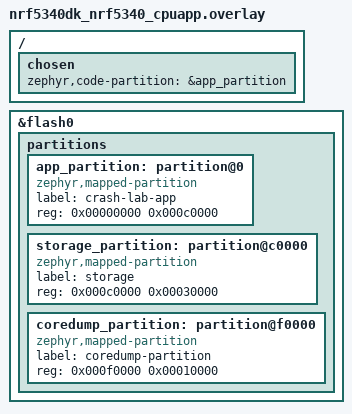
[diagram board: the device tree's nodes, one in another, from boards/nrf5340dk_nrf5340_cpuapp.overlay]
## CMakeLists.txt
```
cmake_minimum_required(VERSION 3.20.0)

list(APPEND ZEPHYR_EXTRA_MODULES "${CMAKE_CURRENT_SOURCE_DIR}")
find_package(Zephyr REQUIRED HINTS $ENV{ZEPHYR_BASE})
project(nrf5340_crash_ble_lab)

execute_process(
  COMMAND git rev-parse --short=12 HEAD
  WORKING_DIRECTORY ${CMAKE_CURRENT_SOURCE_DIR}
  OUTPUT_VARIABLE CRASH_LAB_GIT_SHA
  OUTPUT_STRIP_TRAILING_WHITESPACE
  ERROR_QUIET
)
if(NOT CRASH_LAB_GIT_SHA)
  set(CRASH_LAB_GIT_SHA "uncommitted")
endif()

# A commit without an intervening source edit must also refresh the ID on
# incremental builds (including repositories whose .git is a worktree file).
execute_process(COMMAND git symbolic-ref -q HEAD
  WORKING_DIRECTORY ${CMAKE_CURRENT_SOURCE_DIR}
  OUTPUT_VARIABLE CRASH_LAB_GIT_REF OUTPUT_STRIP_TRAILING_WHITESPACE ERROR_QUIET)
foreach(git_path IN ITEMS HEAD "${CRASH_LAB_GIT_REF}")
  if(git_path)
    execute_process(COMMAND git rev-parse --git-path "${git_path}"
      WORKING_DIRECTORY ${CMAKE_CURRENT_SOURCE_DIR}
      OUTPUT_VARIABLE ref_path OUTPUT_STRIP_TRAILING_WHITESPACE ERROR_QUIET)
    if(ref_path)
      get_filename_component(ref_path "${ref_path}" ABSOLUTE
        BASE_DIR "${CMAKE_CURRENT_SOURCE_DIR}")
      if(EXISTS "${ref_path}")
        set_property(DIRECTORY APPEND PROPERTY CMAKE_CONFIGURE_DEPENDS "${ref_path}")
      endif()
    endif()
  endif()
endforeach()

# A source/config fingerprint travels in BLE status and metadata. Keep the
# unstripped ELF from this build: matching the fingerprint is necessary but
# not a substitute for archiving the precise ELF used to flash the target.
set(CRASH_LAB_INPUTS CMakeLists.txt Kconfig prj.conf sysbuild.conf
  boards/nrf5340dk_nrf5340_cpuapp.overlay
  src/main.c src/crashes.c src/dummy_ble.c src/dump_store.c src/flash_coredump.c
  src/crashes.h src/dummy_ble.h src/dump_store.h src/diagnostics.h src/flash_coredump.h
  sdk/zephyr/src/diag_sdk.c sdk/zephyr/include/diag_sdk/diag_sdk.h
  sdk/zephyr/Kconfig sdk/zephyr/CMakeLists.txt sdk/zephyr/zephyr/module.yml
  zephyr/module.yml)
set(CRASH_LAB_FINGERPRINT "git:${CRASH_LAB_GIT_SHA}\n")
foreach(input IN LISTS CRASH_LAB_INPUTS)
  # A source edit must reconfigure, not just recompile: otherwise a different
  # ELF could advertise an old fingerprint and mis-symbolicate saved events.
  set_property(DIRECTORY APPEND PROPERTY CMAKE_CONFIGURE_DEPENDS
    "${CMAKE_CURRENT_SOURCE_DIR}/${input}")
  file(SHA256 "${CMAKE_CURRENT_SOURCE_DIR}/${input}" digest)
  string(APPEND CRASH_LAB_FINGERPRINT "${input}:${digest}\n")
endforeach()
if(EXISTS "${CMAKE_CURRENT_BINARY_DIR}/zephyr/.config")
  file(SHA256 "${CMAKE_CURRENT_BINARY_DIR}/zephyr/.config" config_digest)
  string(APPEND CRASH_LAB_FINGERPRINT "config:${config_digest}\n")
endif()
string(SHA256 CRASH_LAB_BUILD_FINGERPRINT "${CRASH_LAB_FINGERPRINT}")
string(SUBSTRING "${CRASH_LAB_BUILD_FINGERPRINT}" 0 20 CRASH_LAB_BUILD_FINGERPRINT)

configure_file(src/build_id.h.in ${CMAKE_CURRENT_BINARY_DIR}/generated/build_id.h @ONLY)
target_include_directories(app PRIVATE src ${CMAKE_CURRENT_BINARY_DIR}/generated)

target_sources(app PRIVATE
  src/main.c
  src/crashes.c
  src/dummy_ble.c
  src/dump_store.c
  src/flash_coredump.c
)

# Preserve usable Cortex-M call frames in the unstripped ELF.
target_compile_options(app PRIVATE -fno-omit-frame-pointer -fno-optimize-sibling-calls)
```

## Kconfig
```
mainmenu "nRF5340 crash-over-BLE lab"

source "Kconfig.zephyr"

menu "Crash lab"

config CRASH_LAB_VERSION
	string "Build identifier"
	default "lab-1"
	help
	  Human-readable identifier embedded in firmware and dump metadata.

config CRASH_LAB_AUTO_CRASH
	bool "Enable periodic random crashes"
	default n
	help
	  Keep disabled for first bring-up so BLE remains reachable.

config CRASH_LAB_AUTO_CRASH_SECONDS
	int "Seconds between automatic crashes"
	default 60
	range 10 3600
	depends on CRASH_LAB_AUTO_CRASH

config CRASH_LAB_STACK_SMASH
	bool "Enable optional stack-smash crash type"
	default n
	help
	  Adds crash type 4. Types 0..3 are always available.

config CRASH_LAB_UNSAFE_BLE_COMMANDS
	bool "Allow unauthenticated destructive BLE lab commands"
	default n
	help
	  Exposes intentional crash, reboot, evidence-clear, and synthetic event
	  commands through the custom GATT characteristic. This is only appropriate
	  for an isolated development bench. Leave disabled in derived firmware.

endmenu
```

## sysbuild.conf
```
# The application core uses the network core as the BLE HCI controller.
SB_CONFIG_NETCORE_HCI_IPC=y

# No MCUboot and no OTA slots: this is a wired-flash-only lab image.
SB_CONFIG_BOOTLOADER_MCUBOOT=n
SB_CONFIG_PARTITION_MANAGER=n
```

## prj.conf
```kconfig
# Core runtime
CONFIG_MAIN_STACK_SIZE=4096
CONFIG_SYSTEM_WORKQUEUE_STACK_SIZE=4096
CONFIG_HEAP_MEM_POOL_SIZE=8192
CONFIG_REBOOT=y
CONFIG_HWINFO=y
CONFIG_GPIO=y
CONFIG_ASSERT=y
CONFIG_ASSERT_VERBOSE=y
CONFIG_THREAD_NAME=y
CONFIG_EXTRA_EXCEPTION_INFO=y
CONFIG_DEBUG_OPTIMIZATIONS=y
CONFIG_NO_OPTIMIZATIONS=n
CONFIG_INIT_STACKS=y
CONFIG_STACK_SENTINEL=y
CONFIG_HW_STACK_PROTECTION=y
CONFIG_NULL_POINTER_EXCEPTION_DETECTION_DWT=y

# UART debug stream
CONFIG_SERIAL=y
CONFIG_CONSOLE=y
CONFIG_UART_CONSOLE=y
CONFIG_LOG=y
CONFIG_LOG_MODE_DEFERRED=y
CONFIG_LOG_PROCESS_THREAD_STACK_SIZE=2048
CONFIG_LOG_DEFAULT_LEVEL=3
CONFIG_LOG_MAX_LEVEL=3
CONFIG_LOG_BACKEND_UART=y
CONFIG_LOG_BACKEND_FS=y
CONFIG_LOG_BACKEND_FS_AUTOSTART=n
CONFIG_LOG_BACKEND_FS_DIR="/lfs"
CONFIG_LOG_BACKEND_FS_FILE_PREFIX="zephyr."
CONFIG_LOG_BACKEND_FS_FILE_SIZE=8192
CONFIG_LOG_BACKEND_FS_FILES_LIMIT=4
CONFIG_PRINTK=y
CONFIG_LOG_PRINTK=n

# BLE peripheral on app core; HCI controller comes from hci_ipc net core.
CONFIG_BT=y
CONFIG_BT_PERIPHERAL=y
CONFIG_BT_DEVICE_NAME="crash-lab"
CONFIG_BT_MAX_CONN=1
CONFIG_BT_L2CAP_TX_MTU=498
CONFIG_BT_BUF_ACL_RX_SIZE=502
CONFIG_BT_BUF_ACL_TX_SIZE=502
CONFIG_BT_TX_PROCESSOR_STACK_SIZE=3072
CONFIG_BT_RX_STACK_SIZE=2048
CONFIG_BT_HCI_TX_STACK_SIZE_WITH_PROMPT=y
CONFIG_BT_HCI_TX_STACK_SIZE=2048

# Flash-backed Zephyr binary coredump.
CONFIG_FLASH=y
CONFIG_FLASH_MAP=y
CONFIG_FLASH_PAGE_LAYOUT=y
CONFIG_STREAM_FLASH=y
CONFIG_DEBUG_COREDUMP=y
CONFIG_DEBUG_COREDUMP_BACKEND_OTHER=y
CONFIG_DEBUG_COREDUMP_MEMORY_DUMP_MIN=y
CONFIG_DEBUG_COREDUMP_THREADS_METADATA=y
CONFIG_DEBUG_COREDUMP_THREAD_STACK_TOP=y
CONFIG_DEBUG_COREDUMP_THREAD_STACK_TOP_LIMIT_FOR_CURRENT=8192

# LittleFS archive exposed by MCUmgr filesystem group.
CONFIG_FILE_SYSTEM=y
CONFIG_DIAG_SDK=y
CONFIG_FILE_SYSTEM_LITTLEFS=y
CONFIG_FILE_SYSTEM_MKFS=y
CONFIG_FS_LITTLEFS_FC_HEAP_SIZE=4096
CONFIG_FS_LITTLEFS_CACHE_SIZE=64
CONFIG_FS_LITTLEFS_LOOKAHEAD_SIZE=32
CONFIG_FS_LITTLEFS_PROG_SIZE=4
CONFIG_FS_LITTLEFS_READ_SIZE=4

# SMP over BLE. 2475-byte server buffers improve file-transfer throughput.
CONFIG_MCUMGR=y
CONFIG_MCUMGR_MGMT_NOTIFICATION_HOOKS=y
CONFIG_ZCBOR=y
CONFIG_CRC=y
CONFIG_MCUMGR_TRANSPORT_BT=y
CONFIG_MCUMGR_TRANSPORT_BT_REASSEMBLY=y
CONFIG_MCUMGR_TRANSPORT_NETBUF_SIZE=2475
CONFIG_MCUMGR_TRANSPORT_NETBUF_COUNT=4
CONFIG_MCUMGR_TRANSPORT_WORKQUEUE_STACK_SIZE=4608
CONFIG_MCUMGR_GRP_FS=y
CONFIG_MCUMGR_GRP_FS_MAX_FILE_SIZE_64KB=y
CONFIG_MCUMGR_GRP_FS_FILE_ACCESS_HOOK=y

# Lab policy: automatic crashing starts disabled.
CONFIG_CRASH_LAB_AUTO_CRASH=n
CONFIG_CRASH_LAB_VERSION="lab-1"
CONFIG_CRASH_LAB_UNSAFE_BLE_COMMANDS=y
```

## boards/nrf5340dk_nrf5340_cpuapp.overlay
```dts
/ {
	chosen {
		zephyr,code-partition = &app_partition;
	};
};

/* Replace MCUboot-oriented defaults with a simple lab layout:
 * 0x00000..0xbffff app       (768 KiB)
 * 0xc0000..0xeffff littlefs  (192 KiB)
 * 0xf0000..0xfffff coredump  ( 64 KiB)
 */
/delete-node/ &boot_partition;
/delete-node/ &slot0_partition;
/delete-node/ &slot1_partition;
/delete-node/ &storage_partition;

&flash0 {
	partitions {
		app_partition: partition@0 {
			compatible = "zephyr,mapped-partition";
			label = "crash-lab-app";
			reg = <0x00000000 0x000c0000>;
		};

		storage_partition: partition@c0000 {
			compatible = "zephyr,mapped-partition";
			label = "storage";
			reg = <0x000c0000 0x00030000>;
		};

		coredump_partition: partition@f0000 {
			compatible = "zephyr,mapped-partition";
			label = "coredump-partition";
			reg = <0x000f0000 0x00010000>;
		};
	};
};
```

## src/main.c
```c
#include "build_id.h"
#include "crashes.h"
#include "dummy_ble.h"
#include "dump_store.h"
#include "diagnostics.h"

#include <zephyr/drivers/gpio.h>
#include <zephyr/kernel.h>
#include <zephyr/logging/log.h>
#include <zephyr/sys/reboot.h>

LOG_MODULE_REGISTER(main, LOG_LEVEL_DBG);

static const struct gpio_dt_spec crash_button = GPIO_DT_SPEC_GET(DT_ALIAS(sw0), gpios);
static const struct gpio_dt_spec reboot_button = GPIO_DT_SPEC_GET(DT_ALIAS(sw1), gpios);
static struct gpio_callback crash_button_cb;
static struct gpio_callback reboot_button_cb;
static struct k_work button_crash_work;
static struct k_work button_reboot_work;
static uint8_t next_button_crash;

static void button_crash_handler(struct k_work *work)
{
	ARG_UNUSED(work);
	uint8_t count = IS_ENABLED(CONFIG_CRASH_LAB_STACK_SMASH) ? 5 : 4;
	uint8_t type = next_button_crash++ % count;
	LOG_WRN("Button 1 selected crash type %u (%s)", type, crash_type_name(type));
	int ret = crash_schedule(type);
	if (ret != 0) {
		diagnostics_record("button", DIAG_BUTTON_FAILED, ret);
	}
}

static void button_reboot_handler(struct k_work *work)
{
	ARG_UNUSED(work);
	dump_store_note("clean reboot requested by Button 2");
	sys_reboot(SYS_REBOOT_COLD);
}

static void crash_button_pressed(const struct device *dev, struct gpio_callback *cb,
				 uint32_t pins)
{
	ARG_UNUSED(dev); ARG_UNUSED(cb); ARG_UNUSED(pins);
	k_work_submit(&button_crash_work);
}

static void reboot_button_pressed(const struct device *dev, struct gpio_callback *cb,
				  uint32_t pins)
{
	ARG_UNUSED(dev); ARG_UNUSED(cb); ARG_UNUSED(pins);
	k_work_submit(&button_reboot_work);
}

static int buttons_init(void)
{
	if (!gpio_is_ready_dt(&crash_button) || !gpio_is_ready_dt(&reboot_button)) {
		return -ENODEV;
	}
	int ret = gpio_pin_configure_dt(&crash_button, GPIO_INPUT);
	if (ret == 0) ret = gpio_pin_configure_dt(&reboot_button, GPIO_INPUT);
	if (ret == 0) ret = gpio_pin_interrupt_configure_dt(&crash_button, GPIO_INT_EDGE_TO_ACTIVE);
	if (ret == 0) ret = gpio_pin_interrupt_configure_dt(&reboot_button, GPIO_INT_EDGE_TO_ACTIVE);
	if (ret != 0) return ret;

	k_work_init(&button_crash_work, button_crash_handler);
	k_work_init(&button_reboot_work, button_reboot_handler);
	gpio_init_callback(&crash_button_cb, crash_button_pressed, BIT(crash_button.pin));
	gpio_init_callback(&reboot_button_cb, reboot_button_pressed, BIT(reboot_button.pin));
	gpio_add_callback(crash_button.port, &crash_button_cb);
	gpio_add_callback(reboot_button.port, &reboot_button_cb);
	return 0;
}

int main(void)
{
	printk("CRASHLAB build=%s+%s\n", CONFIG_CRASH_LAB_VERSION, CRASH_LAB_GIT_SHA);
	int ret = dump_store_init();
	if (ret != 0) {
		LOG_ERR("Dump storage initialization failed: %d", ret);
		return ret;
	}
	ret = diagnostics_init();
	if (ret != 0) {
		LOG_ERR("Diagnostic journal initialization failed: %d", ret);
		return ret;
	}
	diagnostics_record("boot", DIAG_BOOT, (int)dump_store_reset_reason());
	LOG_INF("Boot reset_reason=0x%x", dump_store_reset_reason());
	dump_store_note("boot build=%s+%s reset=0x%x", CONFIG_CRASH_LAB_VERSION,
		CRASH_LAB_GIT_SHA, dump_store_reset_reason());

	crash_auto_start();
	ret = buttons_init();
	if (ret != 0) {
		LOG_ERR("Buttons unavailable: %d", ret);
		diagnostics_record("button", DIAG_BUTTON_FAILED, ret);
	}
	ret = dummy_ble_init();
	if (ret != 0) {
		return ret;
	}

	LOG_INF("Ready: BLE command 0=null 1=div0 2=assert 3=fnptr; Button 1 cycles; Button 2 reboots");
	return 0;
}
```

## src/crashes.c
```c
#include "crashes.h"
#include "dump_store.h"
#include "diagnostics.h"

#include <zephyr/kernel.h>
#include <zephyr/logging/log.h>
#include <zephyr/logging/log_ctrl.h>
#include <zephyr/random/random.h>
#include <zephyr/sys/__assert.h>
#include <zephyr/sys/reboot.h>
#include <string.h>

LOG_MODULE_REGISTER(crashes, LOG_LEVEL_DBG);

#define CRASH_FN __attribute__((noinline, used, optimize("O0")))

static struct k_work crash_work;
static uint8_t scheduled_type;

CRASH_FN void crash_null_deref(void)
{
	volatile uint32_t *null_word = (volatile uint32_t *)0;

	*null_word = 0x4e554c4c;
	CODE_UNREACHABLE;
}

CRASH_FN void crash_div_by_zero(void)
{
	volatile int numerator = 12345;
	volatile int denominator = 0;
	volatile int result = numerator / denominator;

	ARG_UNUSED(result);
	CODE_UNREACHABLE;
}

CRASH_FN void crash_assert_fail(void)
{
	__ASSERT(false, "intentional crash_assert_fail");
	CODE_UNREACHABLE;
}

CRASH_FN void crash_bad_fn_ptr(void)
{
	void (*volatile bad_function)(void) = (void (*)(void))0xdeadbee1;

	bad_function();
	CODE_UNREACHABLE;
}

#if defined(CONFIG_CRASH_LAB_STACK_SMASH)
CRASH_FN static void stack_smash_recurse(unsigned int depth)
{
	volatile uint8_t consume[256];

	memset((void *)consume, (int)depth, sizeof(consume));
	stack_smash_recurse(depth + consume[0] + 1);
}

CRASH_FN void crash_stack_smash(void)
{
	stack_smash_recurse(0);
	CODE_UNREACHABLE;
}
#endif

const char *crash_type_name(uint8_t type)
{
	switch (type) {
	case CRASH_NULL_DEREF: return "null";
	case CRASH_DIV_ZERO: return "div0";
	case CRASH_ASSERT: return "assert";
	case CRASH_BAD_FN_PTR: return "fnptr";
	case CRASH_STACK_SMASH: return "stack";
	default: return "unknown";
	}
}

CRASH_FN static void crash_dispatch(uint8_t type)
{
	switch (type) {
	case CRASH_NULL_DEREF: crash_null_deref();
	case CRASH_DIV_ZERO: crash_div_by_zero();
	case CRASH_ASSERT: crash_assert_fail();
	case CRASH_BAD_FN_PTR: crash_bad_fn_ptr();
#if defined(CONFIG_CRASH_LAB_STACK_SMASH)
	case CRASH_STACK_SMASH: crash_stack_smash();
#endif
	default: k_panic();
	}
	CODE_UNREACHABLE;
}

CRASH_FN static void crash_scheduler_work(struct k_work *work)
{
	ARG_UNUSED(work);
	dump_store_note("dispatch crash=%s", crash_type_name(scheduled_type));
	printk("CRASHLAB dispatch=%s\n", crash_type_name(scheduled_type));
	crash_dispatch(scheduled_type);
}

int crash_schedule(uint8_t type)
{
	uint8_t max_type = IS_ENABLED(CONFIG_CRASH_LAB_STACK_SMASH) ? 4 : 3;

	if (type > max_type) {
		return -EINVAL;
	}
	if (k_work_busy_get(&crash_work) != 0) {
		return -EBUSY;
	}
	int ret = dump_store_arm(type);
	if (ret != 0) {
		diagnostics_record("storage", DIAG_COMMAND_FAILED, ret);
		return ret;
	}
	diagnostics_record("crash", DIAG_CRASH_ARMED, type);
	scheduled_type = type;
	return k_work_submit(&crash_work) < 0 ? -EIO : 0;
}

#if defined(CONFIG_CRASH_LAB_AUTO_CRASH)
static struct k_work auto_crash_work;

static void auto_crash_work_handler(struct k_work *work)
{
	ARG_UNUSED(work);
	uint8_t count = IS_ENABLED(CONFIG_CRASH_LAB_STACK_SMASH) ? 5 : 4;
	(void)crash_schedule((uint8_t)(sys_rand32_get() % count));
}

static void auto_crash_timer(struct k_timer *timer)
{
	ARG_UNUSED(timer);
	k_work_submit(&auto_crash_work);
}
K_TIMER_DEFINE(auto_timer, auto_crash_timer, NULL);
#endif

void crash_auto_start(void)
{
	k_work_init(&crash_work, crash_scheduler_work);
#if defined(CONFIG_CRASH_LAB_AUTO_CRASH)
	k_work_init(&auto_crash_work, auto_crash_work_handler);
	k_timer_start(&auto_timer, K_SECONDS(CONFIG_CRASH_LAB_AUTO_CRASH_SECONDS), K_NO_WAIT);
	LOG_WRN("Automatic random crash enabled: %d seconds",
		CONFIG_CRASH_LAB_AUTO_CRASH_SECONDS);
#else
	LOG_INF("Automatic crash disabled; use BLE command or Button 1");
#endif
}

void k_sys_fatal_error_handler(unsigned int reason, const struct arch_esf *esf)
{
	ARG_UNUSED(esf);
	printk("CRASHLAB fatal=%u coredump_attempted; rebooting\n", reason);
	k_busy_wait(200000);
	sys_reboot(SYS_REBOOT_COLD);
	CODE_UNREACHABLE;
}
```

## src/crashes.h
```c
#ifndef CRASH_LAB_CRASHES_H
#define CRASH_LAB_CRASHES_H

#include <stdint.h>

enum crash_lab_type {
	CRASH_NULL_DEREF = 0,
	CRASH_DIV_ZERO = 1,
	CRASH_ASSERT = 2,
	CRASH_BAD_FN_PTR = 3,
	CRASH_STACK_SMASH = 4,
};

const char *crash_type_name(uint8_t type);
int crash_schedule(uint8_t type);
void crash_auto_start(void);

#endif
```

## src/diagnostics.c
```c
#include "diagnostics.h"
#include "build_id.h"

#include <errno.h>
#include <stdlib.h>
#include <string.h>
#include <zephyr/fs/fs.h>
#include <zephyr/kernel.h>

#define EVENTS_PATH "/lfs/events.ndjson"
#define BOOT_COUNT_PATH "/lfs/boot_count.txt"
#define MAX_EVENTS_BYTES 24576

static K_MUTEX_DEFINE(diag_lock);
static uint32_t boot_count;
static uint32_t event_count;
static bool ready;
static void heartbeat_handler(struct k_work *work);
K_WORK_DELAYABLE_DEFINE(heartbeat, heartbeat_handler);

static void heartbeat_handler(struct k_work *work)
{
	ARG_UNUSED(work);
	size_t unused = 0;
	int ret = k_thread_stack_space_get(k_current_get(), &unused);
	diagnostics_record("health", DIAG_HEARTBEAT, ret == 0 ? (int)unused : ret);
	k_work_reschedule(&heartbeat, K_SECONDS(CONFIG_CRASH_LAB_METRICS_INTERVAL_SECONDS));
}

int diagnostics_init(void)
{
	struct fs_file_t file;
	char previous[24] = {0};
	fs_file_t_init(&file);
	if (fs_open(&file, BOOT_COUNT_PATH, FS_O_READ) == 0) {
		ssize_t read = fs_read(&file, previous, sizeof(previous) - 1);
		if (read > 0) {
			boot_count = (uint32_t)strtoul(previous, NULL, 10);
		}
		(void)fs_close(&file);
	}
	boot_count++;
	char next[24];
	snprintk(next, sizeof(next), "%u\n", boot_count);
	fs_file_t_init(&file);
	int ret = fs_open(&file, BOOT_COUNT_PATH, FS_O_CREATE | FS_O_TRUNC | FS_O_WRITE);
	if (ret != 0) {
		return ret;
	}
	if (fs_write(&file, next, strlen(next)) != (ssize_t)strlen(next)) {
		ret = -EIO;
	} else {
		ret = fs_sync(&file);
	}
	(void)fs_close(&file);
	ready = ret == 0;
	if (ready) {
		k_work_schedule(&heartbeat, K_SECONDS(CONFIG_CRASH_LAB_METRICS_INTERVAL_SECONDS));
	}
	return ret;
}

uint32_t diagnostics_boot_count(void) { return boot_count; }
uint32_t diagnostics_event_count(void) { return event_count; }

void diagnostics_log_files(char *buffer, size_t length)
{
	if (length < 3) {
		return;
	}
	buffer[0] = '[';
	buffer[1] = '\0';
	size_t used = 1;
	struct fs_dir_t dir;
	fs_dir_t_init(&dir);
	if (fs_opendir(&dir, "/lfs") == 0) {
		struct fs_dirent entry;
		while (fs_readdir(&dir, &entry) == 0 && entry.name[0] != '\0') {
			if (entry.type != FS_DIR_ENTRY_FILE || strncmp(entry.name, "zephyr.", 7)) {
				continue;
			}
			int added = snprintk(buffer + used, length - used, "%s\"%s\"",
				used > 1 ? "," : "", entry.name);
			if (added <= 0 || added >= length - used - 2) {
				buffer[used] = '\0';
				break;
			}
			used += added;
		}
		(void)fs_closedir(&dir);
	}
	buffer[used++] = ']';
	buffer[used] = '\0';
}

__attribute__((noinline, used))
void diagnostics_record(const char *category, enum diag_code code, int value)
{
	uintptr_t pc = (uintptr_t)__builtin_return_address(0);
	if (!ready || k_is_in_isr()) {
		return;
	}
	/* All categories are static ASCII tokens from this application. Never
	 * embed externally supplied text without JSON escaping. */
	char line[240];
	const char *level = (code == DIAG_BOOT || code == DIAG_BLE_CONNECTED ||
		code == DIAG_BLE_DISCONNECTED || code == DIAG_HEARTBEAT) ? "info" :
		(code == DIAG_CRASH_ARMED || code >= DIAG_INJECT_RECOVERABLE) ? "warning" : "error";
	int n = snprintk(line, sizeof(line),
		"{\"v\":1,\"fingerprint\":\"%s\",\"boot\":%u,"
		"\"uptime_ms\":%lld,\"level\":\"%s\",\"category\":\"%s\",\"code\":%u,"
		"\"value\":%d,\"pc\":\"0x%08x\"}\n",
		CRASH_LAB_FINGERPRINT, boot_count, k_uptime_get(), level, category,
		(unsigned int)code, value, (unsigned int)pc);
	if (n <= 0 || n >= sizeof(line)) {
		return;
	}
	k_mutex_lock(&diag_lock, K_FOREVER);
	struct fs_dirent entry;
	if (fs_stat(EVENTS_PATH, &entry) == 0 && entry.size + n > MAX_EVENTS_BYTES) {
		(void)fs_unlink(EVENTS_PATH);
	}
	struct fs_file_t file;
	fs_file_t_init(&file);
	if (fs_open(&file, EVENTS_PATH, FS_O_CREATE | FS_O_WRITE | FS_O_APPEND) == 0) {
		if (fs_write(&file, line, n) == n && fs_sync(&file) == 0) {
			event_count++;
		}
		(void)fs_close(&file);
	}
	k_mutex_unlock(&diag_lock);
}
```

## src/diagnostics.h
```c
#ifndef CRASH_LAB_DIAGNOSTICS_H
#define CRASH_LAB_DIAGNOSTICS_H

#include <stdint.h>
#include <stddef.h>
#include "build_id.h"
#include <diag_sdk/diag_sdk.h>

/* Code IDs are stable across rebuilds; injection IDs are deliberately separate. */
enum diag_code {
	DIAG_BOOT = 1,
	DIAG_CRASH_ARMED = 2,
	DIAG_BLE_CONNECTED = 10,
	DIAG_BLE_DISCONNECTED = 11,
	DIAG_BLE_START_FAILED = 12,
	DIAG_BLE_ENABLE_FAILED = 13,
	DIAG_COMMAND_FAILED = 14,
	DIAG_BUTTON_FAILED = 15,
	DIAG_HEARTBEAT = 20,
	DIAG_INJECT_RECOVERABLE = 100,
	DIAG_INJECT_BLE_FAILURE = 101,
	DIAG_INJECT_STORAGE_FAILURE = 102,
	DIAG_INJECT_OTA_REJECTED = 103,
};

#define diagnostics_init() diag_sdk_start(CRASH_LAB_FINGERPRINT)
#define diagnostics_boot_count diag_sdk_boot_count
#define diagnostics_event_count diag_sdk_event_count
#define diagnostics_log_files diag_sdk_log_files

/* NOINLINE: return address belongs to the caller, not this function. In
 * addr2line/GDB subtract one byte from the return PC to get the call site.
 * Only use from thread context after the filesystem has been mounted. */
#define DIAGNOSTICS_LEVEL(_code) \
	(((_code) == DIAG_BOOT || (_code) == DIAG_BLE_CONNECTED || \
	  (_code) == DIAG_BLE_DISCONNECTED || (_code) == DIAG_HEARTBEAT) ? \
	 DIAG_SDK_LEVEL_INFO : \
	 (((_code) == DIAG_CRASH_ARMED || (_code) >= DIAG_INJECT_RECOVERABLE) ? \
	  DIAG_SDK_LEVEL_WARNING : DIAG_SDK_LEVEL_ERROR))
#define diagnostics_record(_category, _code, _value) \
	diag_sdk_record(DIAGNOSTICS_LEVEL(_code), (_category), (_code), (_value))

#endif
```

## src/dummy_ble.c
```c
#include "dummy_ble.h"
#include "crashes.h"
#include "dump_store.h"
#include "diagnostics.h"
#include "build_id.h"

#include <errno.h>
#include <string.h>
#include <zephyr/bluetooth/bluetooth.h>
#include <zephyr/bluetooth/conn.h>
#include <zephyr/bluetooth/gatt.h>
#include <zephyr/logging/log.h>
#include <zephyr/mgmt/mcumgr/mgmt/callbacks.h>
#include <zephyr/mgmt/mcumgr/transport/smp_bt.h>
#include <zephyr/sys/reboot.h>

LOG_MODULE_REGISTER(dummy_ble, LOG_LEVEL_DBG);

/* 7a4e0001 = service, 0002 = command, 0003 = status. */
#define CRASH_SERVICE_UUID BT_UUID_128_ENCODE(0x7a4e0001, 0x7b2d, 0x4c19, 0x9a71, 0x1db95c873510)
#define CRASH_COMMAND_UUID BT_UUID_128_ENCODE(0x7a4e0002, 0x7b2d, 0x4c19, 0x9a71, 0x1db95c873510)
#define CRASH_STATUS_UUID  BT_UUID_128_ENCODE(0x7a4e0003, 0x7b2d, 0x4c19, 0x9a71, 0x1db95c873510)

static struct bt_uuid_128 service_uuid = BT_UUID_INIT_128(CRASH_SERVICE_UUID);
static struct bt_uuid_128 command_uuid = BT_UUID_INIT_128(CRASH_COMMAND_UUID);
static struct bt_uuid_128 status_uuid = BT_UUID_INIT_128(CRASH_STATUS_UUID);

static uint8_t pending_command;
static struct k_work command_work;
static struct k_work advertise_work;
static char status_json[384];

static int json_escape(char *output, size_t output_size, const char *input)
{
	size_t used = 0;
	for (; *input != '\0'; ++input) {
		const char *replacement = NULL;
		if (*input == '"') {
			replacement = "\\\"";
		} else if (*input == '\\') {
			replacement = "\\\\";
		} else if ((unsigned char)*input < 0x20) {
			return -EINVAL;
		}
		size_t added = replacement != NULL ? 2 : 1;
		if (used + added >= output_size) {
			return -ENOSPC;
		}
		if (replacement != NULL) {
			memcpy(output + used, replacement, added);
		} else {
			output[used] = *input;
		}
		used += added;
	}
	output[used] = '\0';
	return 0;
}

static int format_status(char *buffer, size_t buffer_size)
{
	char log_files[80];
	char version[96];
	diagnostics_log_files(log_files, sizeof(log_files));
	if (json_escape(version, sizeof(version), CONFIG_CRASH_LAB_VERSION) != 0) {
		return -EINVAL;
	}
	int length = snprintk(buffer, buffer_size,
		"{\"build\":\"%s+%s\",\"fingerprint\":\"%s\",\"uptime_ms\":%lld,\"reset_reason\":%u,"
		"\"dump_pending\":%s,\"dump_size\":%u,\"crash_seq\":%u,"
		"\"boot_count\":%u,\"event_count\":%u,\"unsafe_commands\":%s,\"log_files\":%s}",
		version, CRASH_LAB_GIT_SHA, CRASH_LAB_FINGERPRINT, k_uptime_get(),
		dump_store_reset_reason(), dump_store_pending() ? "true" : "false",
		(unsigned int)dump_store_size(), dump_store_sequence(),
		diagnostics_boot_count(), diagnostics_event_count(),
		IS_ENABLED(CONFIG_CRASH_LAB_UNSAFE_BLE_COMMANDS) ? "true" : "false", log_files);
	return length < 0 || (size_t)length >= buffer_size ? -ENOSPC : length;
}

static ssize_t read_status(struct bt_conn *conn, const struct bt_gatt_attr *attr,
			   void *buf, uint16_t len, uint16_t offset)
{
	ARG_UNUSED(attr);
	/* Freeze one JSON value for all offset reads in this ATT long-read. */
	if (offset == 0 && format_status(status_json, sizeof(status_json)) < 0) {
		return BT_GATT_ERR(BT_ATT_ERR_UNLIKELY);
	}
	return bt_gatt_attr_read(conn, attr, buf, len, offset, status_json, strlen(status_json));
}

static void command_work_handler(struct k_work *work)
{
	ARG_UNUSED(work);
	uint8_t command = pending_command;

	if (command <= (IS_ENABLED(CONFIG_CRASH_LAB_STACK_SMASH) ? 4 : 3)) {
		int ret = crash_schedule(command);
		if (ret != 0) {
			LOG_ERR("Crash schedule failed: %d", ret);
			diagnostics_record("command", DIAG_COMMAND_FAILED, ret);
		}
	} else if (command == 0x10) {
		dump_store_note("clean reboot requested over BLE");
		/* Let the ATT Write Response leave the radio before tearing down HCI. */
		k_sleep(K_MSEC(300));
		sys_reboot(SYS_REBOOT_COLD);
	} else if (command == 0xfe) {
		int ret = dump_store_clear();
		LOG_INF("Dump clear result: %d", ret);
		if (ret != 0) {
			diagnostics_record("storage", DIAG_COMMAND_FAILED, ret);
		}
		dummy_ble_status_changed();
	} else if (command >= 0x20 && command <= 0x23) {
		/* Sample recoverable paths, not claims of real hardware failures. */
		static const enum diag_code cases[] = {
			DIAG_INJECT_RECOVERABLE, DIAG_INJECT_BLE_FAILURE,
			DIAG_INJECT_STORAGE_FAILURE, DIAG_INJECT_OTA_REJECTED,
		};
		diagnostics_record("simulated", cases[command - 0x20], -EIO);
		LOG_WRN("Synthetic diagnostic %u (not a hardware failure)",
			(unsigned int)cases[command - 0x20]);
	}
}

static ssize_t write_command(struct bt_conn *conn, const struct bt_gatt_attr *attr,
			     const void *buf, uint16_t len, uint16_t offset, uint8_t flags)
{
	ARG_UNUSED(conn);
	ARG_UNUSED(attr);
	ARG_UNUSED(flags);
	if (!IS_ENABLED(CONFIG_CRASH_LAB_UNSAFE_BLE_COMMANDS)) {
		return BT_GATT_ERR(BT_ATT_ERR_AUTHORIZATION);
	}
	if (offset != 0 || len != 1) {
		return BT_GATT_ERR(BT_ATT_ERR_INVALID_ATTRIBUTE_LEN);
	}
	uint8_t command = *(const uint8_t *)buf;
	if (command > (IS_ENABLED(CONFIG_CRASH_LAB_STACK_SMASH) ? 4 : 3) &&
	    command != 0x10 && command != 0xfe &&
	    (command < 0x20 || command > 0x23)) {
		diagnostics_record("command", DIAG_COMMAND_FAILED, -EINVAL);
		return BT_GATT_ERR(BT_ATT_ERR_VALUE_NOT_ALLOWED);
	}
	if (k_work_busy_get(&command_work) != 0) {
		return BT_GATT_ERR(BT_ATT_ERR_UNLIKELY);
	}
	pending_command = command;
	k_work_submit(&command_work);
	return len;
}

BT_GATT_SERVICE_DEFINE(crash_service,
	BT_GATT_PRIMARY_SERVICE(&service_uuid),
	BT_GATT_CHARACTERISTIC(&command_uuid.uuid, BT_GATT_CHRC_WRITE,
		BT_GATT_PERM_WRITE, NULL, write_command, NULL),
	BT_GATT_CHARACTERISTIC(&status_uuid.uuid, BT_GATT_CHRC_READ | BT_GATT_CHRC_NOTIFY,
		BT_GATT_PERM_READ, read_status, NULL, status_json),
	BT_GATT_CCC(NULL, BT_GATT_PERM_READ | BT_GATT_PERM_WRITE)
);

void dummy_ble_status_changed(void)
{
	char notification[sizeof(status_json)];
	int length = format_status(notification, sizeof(notification));
	if (length >= 0) {
		(void)bt_gatt_notify(NULL, &crash_service.attrs[4], notification, length);
	}
}

static bool diagnostic_path(const char *filename)
{
	if (strcmp(filename, "/lfs/crash.bin") == 0 ||
	    strcmp(filename, "/lfs/meta.txt") == 0 ||
	    strcmp(filename, "/lfs/recent.log") == 0 ||
	    strcmp(filename, "/lfs/events.ndjson") == 0) {
		return true;
	}
	return strncmp(filename, "/lfs/zephyr.", 12) == 0 && strlen(filename) == 16 &&
		filename[12] >= '0' && filename[12] <= '9' &&
		filename[13] >= '0' && filename[13] <= '9' &&
		filename[14] >= '0' && filename[14] <= '9' &&
		filename[15] >= '0' && filename[15] <= '9';
}

static enum mgmt_cb_return fs_access(uint32_t event, enum mgmt_cb_return previous,
				     int32_t *rc, uint16_t *group, bool *abort_more,
				     void *data, size_t data_size)
{
	ARG_UNUSED(group);
	if (event == MGMT_EVT_OP_FS_MGMT_FILE_ACCESS && previous == MGMT_CB_OK &&
	    data_size == sizeof(struct fs_mgmt_file_access)) {
		struct fs_mgmt_file_access *access = data;
		if ((access->access == FS_MGMT_FILE_ACCESS_READ ||
		     access->access == FS_MGMT_FILE_ACCESS_STATUS) &&
		    diagnostic_path(access->filename)) {
			return MGMT_CB_OK;
		}
		*rc = MGMT_ERR_EACCESSDENIED;
		*abort_more = true;
		return MGMT_CB_ERROR_RC;
	}
	return MGMT_CB_OK;
}

static struct mgmt_callback fs_access_callback = {
	.callback = fs_access,
	.event_id = MGMT_EVT_OP_FS_MGMT_FILE_ACCESS,
};

static const struct bt_data advertising[] = {
	BT_DATA_BYTES(BT_DATA_FLAGS, BT_LE_AD_GENERAL | BT_LE_AD_NO_BREDR),
	BT_DATA_BYTES(BT_DATA_UUID128_ALL, SMP_BT_SVC_UUID_VAL),
};

static const struct bt_data scan_response[] = {
	BT_DATA(BT_DATA_NAME_COMPLETE, CONFIG_BT_DEVICE_NAME,
		sizeof(CONFIG_BT_DEVICE_NAME) - 1),
};

static void start_advertising(void)
{
	int ret = bt_le_adv_start(BT_LE_ADV_CONN_FAST_2, advertising,
		ARRAY_SIZE(advertising), scan_response, ARRAY_SIZE(scan_response));
	if (ret != 0 && ret != -EALREADY) {
		LOG_ERR("Advertising failed: %d", ret);
		diagnostics_record("ble", DIAG_BLE_START_FAILED, ret);
	} else {
		LOG_INF("advertising crash-lab");
	}
}

static void advertise_work_handler(struct k_work *work)
{
	ARG_UNUSED(work);
	start_advertising();
}

static void connected(struct bt_conn *conn, uint8_t err)
{
	ARG_UNUSED(conn);
	LOG_INF("BLE connected, err=%u", err);
	diagnostics_record("ble", DIAG_BLE_CONNECTED, err);
}

static void disconnected(struct bt_conn *conn, uint8_t reason)
{
	ARG_UNUSED(conn);
	LOG_INF("BLE disconnected, reason=%u", reason);
	diagnostics_record("ble", DIAG_BLE_DISCONNECTED, reason);
}

static void recycled(void)
{
	k_work_submit(&advertise_work);
}

BT_CONN_CB_DEFINE(connection_callbacks) = {
	.connected = connected,
	.disconnected = disconnected,
	.recycled = recycled,
};

int dummy_ble_init(void)
{
	k_work_init(&command_work, command_work_handler);
	k_work_init(&advertise_work, advertise_work_handler);
	mgmt_callback_register(&fs_access_callback);
	(void)format_status(status_json, sizeof(status_json));
	int ret = bt_enable(NULL);
	if (ret != 0) {
		LOG_ERR("Bluetooth enable failed: %d", ret);
		diagnostics_record("ble", DIAG_BLE_ENABLE_FAILED, ret);
		return ret;
	}
	start_advertising();
	return 0;
}
```

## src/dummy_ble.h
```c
#ifndef CRASH_LAB_DUMMY_BLE_H
#define CRASH_LAB_DUMMY_BLE_H

int dummy_ble_init(void);
void dummy_ble_status_changed(void);

#endif
```

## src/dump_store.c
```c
#include "dump_store.h"
#include "crashes.h"
#include "flash_coredump.h"
#include "build_id.h"

#include <stdarg.h>
#include <stdio.h>
#include <stdlib.h>
#include <string.h>
#include <zephyr/debug/coredump.h>
#include <zephyr/fs/fs.h>
#include <zephyr/fs/littlefs.h>
#include <zephyr/drivers/hwinfo.h>
#include <zephyr/logging/log.h>
#include <zephyr/storage/flash_map.h>

LOG_MODULE_REGISTER(dump_store, LOG_LEVEL_DBG);

#define STORAGE_PARTITION storage_partition
#define STORAGE_ID PARTITION_ID(STORAGE_PARTITION)
#define CRASH_PATH "/lfs/crash.bin"
#define CRASH_TEMP_PATH "/lfs/crash.tmp"
#define META_PATH "/lfs/meta.txt"
#define LOG_PATH "/lfs/recent.log"
#define ARMED_PATH "/lfs/armed.txt"
#define SEQ_PATH "/lfs/sequence.txt"

FS_LITTLEFS_DECLARE_DEFAULT_CONFIG(storage);

static struct fs_mount_t littlefs_mount = {
	.type = FS_LITTLEFS,
	.fs_data = &storage,
	.storage_dev = (void *)STORAGE_ID,
	.mnt_point = "/lfs",
};

static K_MUTEX_DEFINE(store_lock);
static bool pending;
static size_t saved_size;
static uint32_t reset_reason;
static uint32_t sequence;

static int write_text(const char *path, const char *text)
{
	char temporary[64];
	if (snprintk(temporary, sizeof(temporary), "%s.tmp", path) >= sizeof(temporary)) {
		return -ENAMETOOLONG;
	}
	struct fs_file_t file;
	fs_file_t_init(&file);
	int ret = fs_open(&file, temporary, FS_O_CREATE | FS_O_WRITE | FS_O_TRUNC);
	if (ret == 0) {
		ssize_t wrote = fs_write(&file, text, strlen(text));
		ret = wrote == (ssize_t)strlen(text) ? fs_sync(&file) : -EIO;
	}
	(void)fs_close(&file);
	if (ret == 0) {
		ret = fs_rename(temporary, path);
	}
	if (ret != 0) {
		(void)fs_unlink(temporary);
	}
	return ret;
}

static int read_u32(const char *path, uint32_t *value)
{
	char buf[24] = {0};
	struct fs_file_t file;
	fs_file_t_init(&file);
	int ret = fs_open(&file, path, FS_O_READ);
	if (ret != 0) {
		return ret;
	}
	ssize_t got = fs_read(&file, buf, sizeof(buf) - 1);
	(void)fs_close(&file);
	if (got <= 0) {
		return -EIO;
	}
	*value = (uint32_t)strtoul(buf, NULL, 10);
	return 0;
}

static int copy_coredump_to_file(void)
{
	int size = coredump_query(COREDUMP_QUERY_GET_STORED_DUMP_SIZE, NULL);
	if (size <= 0) {
		return size;
	}
	if (size > 65536) {
		return -EFBIG;
	}
	if (coredump_cmd(COREDUMP_CMD_VERIFY_STORED_DUMP, NULL) != 1) {
		return -EBADMSG;
	}
	char crash_fingerprint[21];
	int ret = flash_coredump_build_fingerprint(crash_fingerprint);
	if (ret != 0) {
		return ret;
	}

	struct fs_file_t file;
	fs_file_t_init(&file);
	ret = fs_open(&file, CRASH_TEMP_PATH, FS_O_CREATE | FS_O_WRITE | FS_O_TRUNC);
	if (ret != 0) {
		return ret;
	}

	uint8_t buffer[512];
	for (off_t offset = 0; offset < size;) {
		size_t length = MIN(sizeof(buffer), (size_t)(size - offset));
		struct coredump_cmd_copy_arg copy = {
			.offset = offset,
			.buffer = buffer,
			.length = length,
		};
		ret = coredump_cmd(COREDUMP_CMD_COPY_STORED_DUMP, &copy);
		if (ret != (int)length || fs_write(&file, buffer, length) != (ssize_t)length) {
			ret = -EIO;
			break;
		}
		offset += length;
	}
	if (ret >= 0) {
		ret = fs_sync(&file);
	}
	(void)fs_close(&file);
	if (ret != 0) {
		(void)fs_unlink(CRASH_TEMP_PATH);
		return ret;
	}
	ret = fs_rename(CRASH_TEMP_PATH, CRASH_PATH);
	if (ret != 0) {
		(void)fs_unlink(CRASH_TEMP_PATH);
		return ret;
	}

	saved_size = (size_t)size;
	pending = true;
	sequence++;
	char seq[24];
	snprintk(seq, sizeof(seq), "%u\n", sequence);
	(void)write_text(SEQ_PATH, seq);

	char armed[32] = "unknown";
	struct fs_file_t af;
	fs_file_t_init(&af);
	if (fs_open(&af, ARMED_PATH, FS_O_READ) == 0) {
		ssize_t got = fs_read(&af, armed, sizeof(armed) - 1);
		if (got > 0) {
			armed[got] = '\0';
		}
		(void)fs_close(&af);
	}

	char meta[320];
	snprintk(meta, sizeof(meta),
		"{\"build\":\"%s+%s\",\"fingerprint\":\"%s\","
		"\"collector_fingerprint\":\"%s\",\"version\":\"%s\","
		"\"crash_seq\":%u,\"reset_reason\":%u,\"expected\":\"%s\","
		"\"dump_size\":%u}\n",
		CONFIG_CRASH_LAB_VERSION, CRASH_LAB_GIT_SHA, crash_fingerprint,
		CRASH_LAB_FINGERPRINT,
		CONFIG_CRASH_LAB_VERSION,
		sequence, reset_reason, armed, (unsigned int)saved_size);
	ret = write_text(META_PATH, meta);
	if (ret == 0) {
		ret = coredump_cmd(COREDUMP_CMD_INVALIDATE_STORED_DUMP, NULL);
	}
	return ret;
}

int dump_store_init(void)
{
	(void)hwinfo_get_reset_cause(&reset_reason);
	(void)hwinfo_clear_reset_cause();

	int ret = fs_mount(&littlefs_mount);
	if (ret != 0) {
		/* Format only a blank device. Corrupt/older littlefs must be preserved
		 * for investigation rather than silently destroying crash evidence. */
		const struct flash_area *area;
		uint32_t first_word = 0;
		int flash_ret = flash_area_open(STORAGE_ID, &area);
		if (flash_ret == 0) {
			flash_ret = flash_area_read(area, 0, &first_word, sizeof(first_word));
			flash_area_close(area);
		}
		if (flash_ret != 0 || first_word != UINT32_MAX) {
			LOG_ERR("littlefs mount failed (%d); nonblank storage preserved", ret);
			return ret;
		}
		LOG_WRN("Formatting erased lab littlefs partition");
		ret = fs_mkfs(FS_LITTLEFS, (uintptr_t)littlefs_mount.storage_dev,
			littlefs_mount.fs_data, 0);
		if (ret == 0) {
			ret = fs_mount(&littlefs_mount);
		}
	}
	if (ret != 0) {
		LOG_ERR("littlefs unavailable: %d", ret);
		return ret;
	}
	(void)read_u32(SEQ_PATH, &sequence);

	struct fs_dirent entry;
	if (fs_stat(CRASH_PATH, &entry) == 0 && entry.size > 0) {
		pending = true;
		saved_size = entry.size;
	}

	int has_dump = coredump_query(COREDUMP_QUERY_HAS_STORED_DUMP, NULL);
	printk("CRASHLAB flash_dump_valid=%d raw_size=%d backend_error=%d\n", has_dump,
		coredump_query(COREDUMP_QUERY_GET_STORED_DUMP_SIZE, NULL),
		coredump_query(COREDUMP_QUERY_GET_ERROR, NULL));
	if (has_dump == 1) {
		ret = copy_coredump_to_file();
		if (ret == 0) {
			LOG_INF("dump pending / copied to %s (%u bytes)", CRASH_PATH,
				(unsigned int)saved_size);
		} else {
			LOG_ERR("coredump copy failed: %d", ret);
			return ret;
		}
	}
	return 0;
}

void dump_store_note(const char *fmt, ...)
{
	char line[160];
	va_list ap;
	va_start(ap, fmt);
	vsnprintk(line, sizeof(line), fmt, ap);
	va_end(ap);

	k_mutex_lock(&store_lock, K_FOREVER);
	struct fs_dirent log_entry;
	if (fs_stat(LOG_PATH, &log_entry) == 0 && log_entry.size > 16384) {
		(void)fs_unlink(LOG_PATH);
	}
	struct fs_file_t file;
	fs_file_t_init(&file);
	if (fs_open(&file, LOG_PATH, FS_O_CREATE | FS_O_WRITE | FS_O_APPEND) == 0) {
		(void)fs_write(&file, line, strlen(line));
		(void)fs_write(&file, "\n", 1);
		(void)fs_sync(&file);
		(void)fs_close(&file);
	}
	k_mutex_unlock(&store_lock);
}

int dump_store_arm(uint8_t type)
{
	const char *name = crash_type_name(type);
	int ret = write_text(ARMED_PATH, name);
	if (ret == 0) {
		dump_store_note("armed crash=%s uptime_ms=%lld", name, k_uptime_get());
	}
	return ret;
}

bool dump_store_pending(void) { return pending; }
size_t dump_store_size(void) { return saved_size; }
uint32_t dump_store_reset_reason(void) { return reset_reason; }
uint32_t dump_store_sequence(void) { return sequence; }

int dump_store_clear(void)
{
	const char *paths[] = {CRASH_PATH, META_PATH, LOG_PATH, ARMED_PATH, CRASH_TEMP_PATH};
	int first_error = 0;
	for (size_t i = 0; i < ARRAY_SIZE(paths); ++i) {
		int ret = fs_unlink(paths[i]);
		if (ret != 0 && ret != -ENOENT && first_error == 0) {
			first_error = ret;
		}
	}
	int ret = coredump_cmd(COREDUMP_CMD_ERASE_STORED_DUMP, NULL);
	if (ret != 0 && first_error == 0) {
		first_error = ret;
	}
	if (first_error == 0) {
		pending = false;
		saved_size = 0;
	}
	return first_error;
}
```

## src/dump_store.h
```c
#ifndef CRASH_LAB_DUMP_STORE_H
#define CRASH_LAB_DUMP_STORE_H

#include <stdbool.h>
#include <stddef.h>
#include <stdint.h>

int dump_store_init(void);
void dump_store_note(const char *fmt, ...);
int dump_store_arm(uint8_t type);
bool dump_store_pending(void);
size_t dump_store_size(void);
uint32_t dump_store_reset_reason(void);
uint32_t dump_store_sequence(void);
int dump_store_clear(void);

#endif
```

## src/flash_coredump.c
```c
/* Standalone fault-context nRF5340 internal-flash Zephyr coredump backend.
 *
 * soc_flash_nrf.c serializes writes using k_sem_take(K_FOREVER), which asserts
 * in exception context when CONFIG_ASSERT=y. The generic flash-partition
 * backend therefore cannot capture an actual Cortex-M fault on this build.
 * The fault path here calls synchronous nrfx NVMC directly, without kernel
 * locks, allocation, logging or the filesystem. The littlefs side never uses
 * this partition. This lab must not trigger faults during an active flash
 * operation or run another app-core writer while the dump is being saved.
 */
#include "flash_coredump.h"
#include "build_id.h"
#include <errno.h>
#include <string.h>
#include <nrfx_nvmc.h>
#include <zephyr/debug/coredump.h>
#include <zephyr/storage/flash_map.h>

#define DUMP_NODE coredump_partition
#define DUMP_START PARTITION_OFFSET(DUMP_NODE)
#define DUMP_BYTES PARTITION_SIZE(DUMP_NODE)
#define HEADER_BYTES 36U
#define MAGIC 0x42444c43U /* "CLDB" in little endian */
#define HEADER_VERSION 1U

BUILD_ASSERT(DUMP_BYTES == 65536U, "The lab uses a 64 KiB crash partition");
BUILD_ASSERT((DUMP_START % 4096) == 0, "NVMC erase requires page alignment");

static uint32_t length;
static uint32_t checksum;
static int last_error;
static uint8_t partial[4];
static uint8_t partial_len;

static inline uint32_t flash_word(uint32_t byte_offset)
{
	return *(volatile const uint32_t *)(uintptr_t)(DUMP_START + byte_offset);
}

static void program_word(uint32_t byte_offset, uint32_t value)
{
	nrfx_nvmc_word_write(DUMP_START + byte_offset, value);
	while (!nrfx_nvmc_write_done_check()) {
	}
}

static int erase_all(void)
{
	uint32_t page_size = nrfx_nvmc_flash_page_size_get();
	if (page_size == 0 || DUMP_START % page_size || DUMP_BYTES % page_size) {
		return -EINVAL;
	}
	for (uint32_t i = 0; i < DUMP_BYTES; i += page_size) {
		int ret = nrfx_nvmc_page_erase(DUMP_START + i);
		if (ret != 0) {
			return ret;
		}
	}
	return 0;
}

static void start(void)
{
	length = 0;
	checksum = 0;
	partial_len = 0;
	last_error = erase_all();
}

static void write_buffer(uint8_t *buffer, size_t size)
{
	if (last_error != 0) {
		return;
	}
	for (size_t i = 0; i < size; ++i) {
		if (length >= DUMP_BYTES - HEADER_BYTES) {
			last_error = -ENOSPC;
			return;
		}
		uint8_t byte = buffer[i];
		partial[partial_len++] = byte;
		checksum += byte;
		length++;
		if (partial_len == 4) {
			uint32_t word;
			memcpy(&word, partial, sizeof(word));
			program_word(HEADER_BYTES + length - 4, word);
			partial_len = 0;
		}
	}
}

static void end(void)
{
	if (last_error != 0) {
		return; /* no magic: never publish a partial dump */
	}
	if (partial_len != 0) {
		uint32_t word = UINT32_MAX;
		memcpy(&word, partial, partial_len);
		program_word(HEADER_BYTES + length - partial_len, word);
	}
	program_word(4, length);
	program_word(8, checksum);
	program_word(12, HEADER_VERSION);
	for (uint32_t i = 0; i < 20; i += 4) {
		uint32_t word;
		memcpy(&word, CRASH_LAB_FINGERPRINT + i, sizeof(word));
		program_word(16 + i, word);
	}
	program_word(0, MAGIC); /* commit marker, written only after all data */
}

static int stored_size(void)
{
	uint32_t size = flash_word(4);
	if (flash_word(0) != MAGIC || flash_word(12) != HEADER_VERSION ||
	    size < 17 || size > DUMP_BYTES - HEADER_BYTES) {
		return 0;
	}
	return (int)size;
}

int flash_coredump_build_fingerprint(char output[21])
{
	if (output == NULL || stored_size() <= 0) {
		return -EINVAL;
	}
	memcpy(output, (const void *)(uintptr_t)(DUMP_START + 16), 20);
	output[20] = '\0';
	for (size_t i = 0; i < 20; ++i) {
		if (!((output[i] >= '0' && output[i] <= '9') ||
		      (output[i] >= 'a' && output[i] <= 'f'))) {
			return -EBADMSG;
		}
	}
	return 0;
}

static int verify(void)
{
	int size = stored_size();
	if (size <= 0) {
		return size;
	}
	uint32_t sum = 0;
	const uint8_t *payload = (const uint8_t *)(uintptr_t)(DUMP_START + HEADER_BYTES);
	for (int i = 0; i < size; ++i) {
		sum += payload[i];
	}
	return sum == flash_word(8) ? 1 : 0;
}

static int query(enum coredump_query_id id, void *arg)
{
	ARG_UNUSED(arg);
	switch (id) {
	case COREDUMP_QUERY_GET_ERROR: return last_error;
	case COREDUMP_QUERY_HAS_STORED_DUMP: return verify();
	case COREDUMP_QUERY_GET_STORED_DUMP_SIZE: return stored_size();
	default: return -ENOTSUP;
	}
}

static int command(enum coredump_cmd_id id, void *arg)
{
	switch (id) {
	case COREDUMP_CMD_CLEAR_ERROR:
		last_error = 0;
		return 0;
	case COREDUMP_CMD_VERIFY_STORED_DUMP:
		return verify();
	case COREDUMP_CMD_COPY_STORED_DUMP: {
		struct coredump_cmd_copy_arg *copy = arg;
		int size = stored_size();
		if (!copy || !copy->buffer || copy->offset < 0 ||
		    copy->offset > size || copy->length > size - copy->offset) {
			return -EINVAL;
		}
		memcpy(copy->buffer,
		       (const void *)(uintptr_t)(DUMP_START + HEADER_BYTES + copy->offset),
		       copy->length);
		return (int)copy->length;
	}
	case COREDUMP_CMD_INVALIDATE_STORED_DUMP:
		if (stored_size() > 0) {
			program_word(0, 0); /* only clear bits; no blocking kernel lock */
		}
		return 0;
	case COREDUMP_CMD_ERASE_STORED_DUMP:
		return erase_all();
	default: return -ENOTSUP;
	}
}

struct coredump_backend_api coredump_backend_other = {
	.start = start,
	.end = end,
	.buffer_output = write_buffer,
	.query = query,
	.cmd = command,
};
```

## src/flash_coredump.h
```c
#ifndef CRASH_LAB_FLASH_COREDUMP_H
#define CRASH_LAB_FLASH_COREDUMP_H

/* Returns the build fingerprint committed with the raw fault-time dump. */
int flash_coredump_build_fingerprint(char output[21]);

#endif
```
